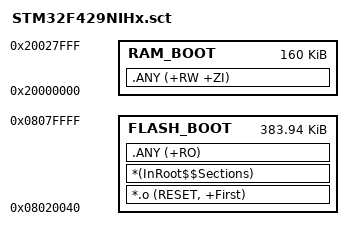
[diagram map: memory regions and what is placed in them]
; ***********************************************************************
; *** Scatter-Loading Description File generated by Blu5 View Pte Ltd ***
; ***********************************************************************


FLASH_USB_BOOT_SECTOR_5 0x08020040 (0x5FFC0)  { 	      	; load region size_region

    FLASH_BOOT	 0x08020040 (0x5FFC0)             	; USB BOOT PrgCode load address = execution address
    {
        *.o (RESET, +First)
        *(InRoot$$Sections)
        .ANY (+RO)
		
	}


    RAM_BOOT 0x20000000 (0x28000)  					; SRAM reserved for USB BOOT (len 0x28000)
    {
        .ANY (+RW +ZI)
    }


}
